# AST1080 register map
File version: 1.0
CPU: CM4 r0p1, little endian, MPU, FPU, 4 interrupt priority bits, 256 interrupts
Registers are 32-bit, read-write, reset 0x0 unless marked. A register's access mark holds for its fields unless they carry their own. Offsets are from the block's base; [hi:lo] are bit positions; {n}, {i} and the like mark numbered series.

## pric_io (part 3 of 3)
Base 0x74100000
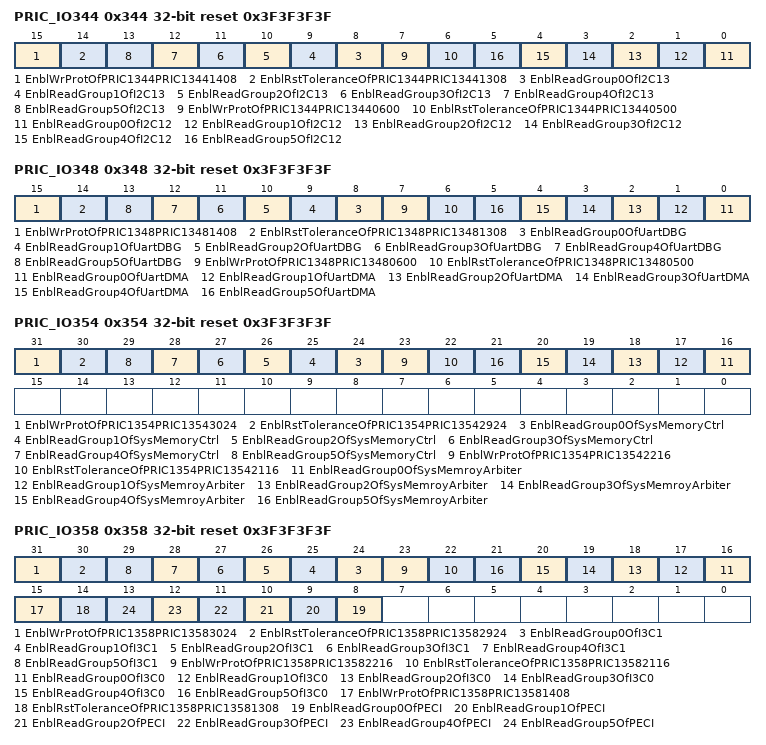
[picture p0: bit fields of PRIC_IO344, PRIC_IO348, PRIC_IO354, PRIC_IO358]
0x344 PRIC_IO344 reset 0x3F3F3F3F — Slave Read Group Setting Register \#17
  [15] EnblWrProtOfPRIC1344PRIC13441408 — Enable Write Protection of PRIC1344PRIC1_344[14:08]
  [14] EnblRstToleranceOfPRIC1344PRIC13441308 — Enable Reset Tolerance of PRIC1344PRIC1_344[13:08]
    0=Reset_By_SRST; 1=Reset_By_SRST_And_PSP_Reset
  [n+8] EnblReadGroup{n}OfI2C13 (n=0..5) — Enable Read Group #{n} of I2C13
  [7] EnblWrProtOfPRIC1344PRIC13440600 — Enable Write Protection of PRIC1344PRIC1_344[06:00]
  [6] EnblRstToleranceOfPRIC1344PRIC13440500 — Enable Reset Tolerance of PRIC1344PRIC1_344[05:00]
    0=Reset_By_SRST; 1=Reset_By_SRST_And_PSP_Reset
  [n] EnblReadGroup{n}OfI2C12 (n=0..5) — Enable Read Group #{n} of I2C12
0x348 PRIC_IO348 reset 0x3F3F3F3F — Slave Read Group Setting Register \#18
  [15] EnblWrProtOfPRIC1348PRIC13481408 — Enable Write Protection of PRIC1348PRIC1_348[14:08]
  [14] EnblRstToleranceOfPRIC1348PRIC13481308 — Enable Reset Tolerance of PRIC1348PRIC1_348[13:08]
    0=Reset_By_SRST; 1=Reset_By_SRST_And_PSP_Reset
  [n+8] EnblReadGroup{n}OfUartDBG (n=0..5) — Enable Read Group #{n} of UartDBG
  [7] EnblWrProtOfPRIC1348PRIC13480600 — Enable Write Protection of PRIC1348PRIC1_348[06:00]
  [6] EnblRstToleranceOfPRIC1348PRIC13480500 — Enable Reset Tolerance of PRIC1348PRIC1_348[05:00]
    0=Reset_By_SRST; 1=Reset_By_SRST_And_PSP_Reset
  [n] EnblReadGroup{n}OfUartDMA (n=0..5) — Enable Read Group #{n} of UartDMA
0x34C PRIC_IO34C reset 0x3F3F3F3F (reset mask 0x0) — Slave Read Group Setting Register \#19
0x350 PRIC_IO350 reset 0x3F3F3F3F (reset mask 0x0) — Slave Read Group Setting Register \#20
0x354 PRIC_IO354 reset 0x3F3F3F3F — Slave Read Group Setting Register \#21
  [31] EnblWrProtOfPRIC1354PRIC13543024 — Enable Write Protection of PRIC1354PRIC1_354[30:24]
  [30] EnblRstToleranceOfPRIC1354PRIC13542924 — Enable Reset Tolerance of PRIC1354PRIC1_354[29:24]
    0=Reset_By_SRST; 1=Reset_By_SRST_And_PSP_Reset
  [n+24] EnblReadGroup{n}OfSysMemoryCtrl (n=0..5) — Enable Read Group #{n} of System Memory Controller
  [23] EnblWrProtOfPRIC1354PRIC13542216 — Enable Write Protection of PRIC1354PRIC1_354[22:16]
  [22] EnblRstToleranceOfPRIC1354PRIC13542116 — Enable Reset Tolerance of PRIC1354PRIC1_354[21:16]
    0=Reset_By_SRST; 1=Reset_By_SRST_And_PSP_Reset
  [n+16] EnblReadGroup{n}OfSysMemroyArbiter (n=0..5) — Enable Read Group #{n} of System Memroy Arbiter
0x358 PRIC_IO358 reset 0x3F3F3F3F — Slave Read Group Setting Register \#22
  [31] EnblWrProtOfPRIC1358PRIC13583024 — Enable Write Protection of PRIC1358PRIC1_358[30:24]
  [30] EnblRstToleranceOfPRIC1358PRIC13582924 — Enable Reset Tolerance of PRIC1358PRIC1_358[29:24]
    0=Reset_By_SRST; 1=Reset_By_SRST_And_PSP_Reset
  [n+24] EnblReadGroup{n}OfI3C1 (n=0..5) — Enable Read Group #{n} of I3C1
  [23] EnblWrProtOfPRIC1358PRIC13582216 — Enable Write Protection of PRIC1358PRIC1_358[22:16]
  [22] EnblRstToleranceOfPRIC1358PRIC13582116 — Enable Reset Tolerance of PRIC1358PRIC1_358[21:16]
    0=Reset_By_SRST; 1=Reset_By_SRST_And_PSP_Reset
  [n+16] EnblReadGroup{n}OfI3C0 (n=0..5) — Enable Read Group #{n} of I3C0
  [15] EnblWrProtOfPRIC1358PRIC13581408 — Enable Write Protection of PRIC1358PRIC1_358[14:08]
  [14] EnblRstToleranceOfPRIC1358PRIC13581308 — Enable Reset Tolerance of PRIC1358PRIC1_358[13:08]
    0=Reset_By_SRST; 1=Reset_By_SRST_And_PSP_Reset
  [n+8] EnblReadGroup{n}OfPECI (n=0..5) — Enable Read Group #{n} of PECI
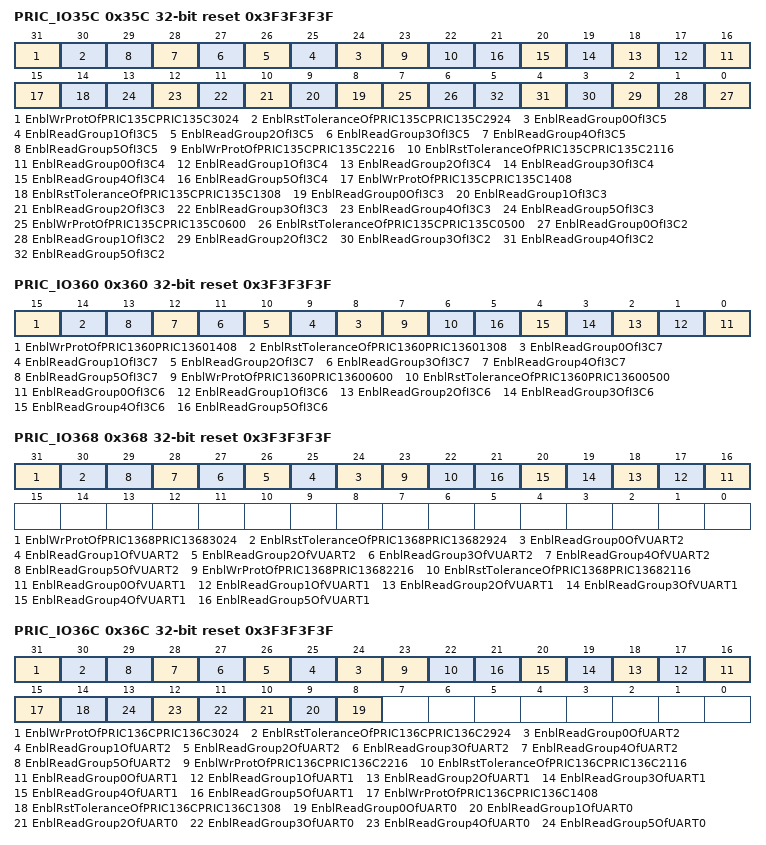
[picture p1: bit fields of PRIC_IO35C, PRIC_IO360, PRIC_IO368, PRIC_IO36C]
0x35C PRIC_IO35C reset 0x3F3F3F3F — Slave Read Group Setting Register \#23
  [31] EnblWrProtOfPRIC135CPRIC135C3024 — Enable Write Protection of PRIC135CPRIC1_35C[30:24]
  [30] EnblRstToleranceOfPRIC135CPRIC135C2924 — Enable Reset Tolerance of PRIC135CPRIC1_35C[29:24]
    0=Reset_By_SRST; 1=Reset_By_SRST_And_PSP_Reset
  [n+24] EnblReadGroup{n}OfI3C5 (n=0..5) — Enable Read Group #{n} of I3C5
  [23] EnblWrProtOfPRIC135CPRIC135C2216 — Enable Write Protection of PRIC135CPRIC1_35C[22:16]
  [22] EnblRstToleranceOfPRIC135CPRIC135C2116 — Enable Reset Tolerance of PRIC135CPRIC1_35C[21:16]
    0=Reset_By_SRST; 1=Reset_By_SRST_And_PSP_Reset
  [n+16] EnblReadGroup{n}OfI3C4 (n=0..5) — Enable Read Group #{n} of I3C4
  [15] EnblWrProtOfPRIC135CPRIC135C1408 — Enable Write Protection of PRIC135CPRIC1_35C[14:08]
  [14] EnblRstToleranceOfPRIC135CPRIC135C1308 — Enable Reset Tolerance of PRIC135CPRIC1_35C[13:08]
    0=Reset_By_SRST; 1=Reset_By_SRST_And_PSP_Reset
  [n+8] EnblReadGroup{n}OfI3C3 (n=0..5) — Enable Read Group #{n} of I3C3
  [7] EnblWrProtOfPRIC135CPRIC135C0600 — Enable Write Protection of PRIC135CPRIC1_35C[06:00]
  [6] EnblRstToleranceOfPRIC135CPRIC135C0500 — Enable Reset Tolerance of PRIC135CPRIC1_35C[05:00]
    0=Reset_By_SRST; 1=Reset_By_SRST_And_PSP_Reset
  [n] EnblReadGroup{n}OfI3C2 (n=0..5) — Enable Read Group #{n} of I3C2
0x360 PRIC_IO360 reset 0x3F3F3F3F — Slave Read Group Setting Register \#24
  [15] EnblWrProtOfPRIC1360PRIC13601408 — Enable Write Protection of PRIC1360PRIC1_360[14:08]
  [14] EnblRstToleranceOfPRIC1360PRIC13601308 — Enable Reset Tolerance of PRIC1360PRIC1_360[13:08]
    0=Reset_By_SRST; 1=Reset_By_SRST_And_PSP_Reset
  [n+8] EnblReadGroup{n}OfI3C7 (n=0..5) — Enable Read Group #{n} of I3C7
  [7] EnblWrProtOfPRIC1360PRIC13600600 — Enable Write Protection of PRIC1360PRIC1_360[06:00]
  [6] EnblRstToleranceOfPRIC1360PRIC13600500 — Enable Reset Tolerance of PRIC1360PRIC1_360[05:00]
    0=Reset_By_SRST; 1=Reset_By_SRST_And_PSP_Reset
  [n] EnblReadGroup{n}OfI3C6 (n=0..5) — Enable Read Group #{n} of I3C6
0x364 PRIC_IO364 reset 0x3F3F3F3F (reset mask 0x0) — Slave Read Group Setting Register \#25
0x368 PRIC_IO368 reset 0x3F3F3F3F — Slave Read Group Setting Register \#26
  [31] EnblWrProtOfPRIC1368PRIC13683024 — Enable Write Protection of PRIC1368PRIC1_368[30:24]
  [30] EnblRstToleranceOfPRIC1368PRIC13682924 — Enable Reset Tolerance of PRIC1368PRIC1_368[29:24]
    0=Reset_By_SRST; 1=Reset_By_SRST_And_PSP_Reset
  [n+24] EnblReadGroup{n}OfVUART2 (n=0..5) — Enable Read Group #{n} of VUART2
  [23] EnblWrProtOfPRIC1368PRIC13682216 — Enable Write Protection of PRIC1368PRIC1_368[22:16]
  [22] EnblRstToleranceOfPRIC1368PRIC13682116 — Enable Reset Tolerance of PRIC1368PRIC1_368[21:16]
    0=Reset_By_SRST; 1=Reset_By_SRST_And_PSP_Reset
  [n+16] EnblReadGroup{n}OfVUART1 (n=0..5) — Enable Read Group #{n} of VUART1
0x36C PRIC_IO36C reset 0x3F3F3F3F — Slave Read Group Setting Register \#27
  [31] EnblWrProtOfPRIC136CPRIC136C3024 — Enable Write Protection of PRIC136CPRIC1_36C[30:24]
  [30] EnblRstToleranceOfPRIC136CPRIC136C2924 — Enable Reset Tolerance of PRIC136CPRIC1_36C[29:24]
    0=Reset_By_SRST; 1=Reset_By_SRST_And_PSP_Reset
  [n+24] EnblReadGroup{n}OfUART2 (n=0..5) — Enable Read Group #{n} of UART2
  [23] EnblWrProtOfPRIC136CPRIC136C2216 — Enable Write Protection of PRIC136CPRIC1_36C[22:16]
  [22] EnblRstToleranceOfPRIC136CPRIC136C2116 — Enable Reset Tolerance of PRIC136CPRIC1_36C[21:16]
    0=Reset_By_SRST; 1=Reset_By_SRST_And_PSP_Reset
  [n+16] EnblReadGroup{n}OfUART1 (n=0..5) — Enable Read Group #{n} of UART1
  [15] EnblWrProtOfPRIC136CPRIC136C1408 — Enable Write Protection of PRIC136CPRIC1_36C[14:08]
  [14] EnblRstToleranceOfPRIC136CPRIC136C1308 — Enable Reset Tolerance of PRIC136CPRIC1_36C[13:08]
    0=Reset_By_SRST; 1=Reset_By_SRST_And_PSP_Reset
  [n+8] EnblReadGroup{n}OfUART0 (n=0..5) — Enable Read Group #{n} of UART0
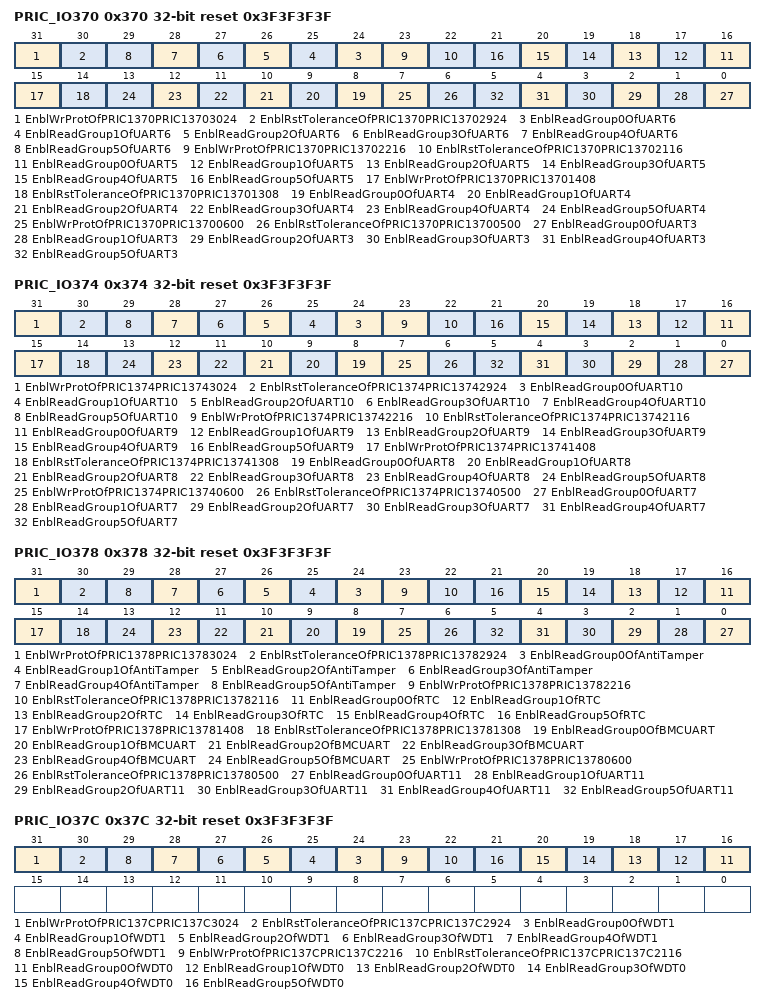
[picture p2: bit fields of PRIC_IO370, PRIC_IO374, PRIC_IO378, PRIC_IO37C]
0x370 PRIC_IO370 reset 0x3F3F3F3F — Slave Read Group Setting Register \#28
  [31] EnblWrProtOfPRIC1370PRIC13703024 — Enable Write Protection of PRIC1370PRIC1_370[30:24]
  [30] EnblRstToleranceOfPRIC1370PRIC13702924 — Enable Reset Tolerance of PRIC1370PRIC1_370[29:24]
    0=Reset_By_SRST; 1=Reset_By_SRST_And_PSP_Reset
  [n+24] EnblReadGroup{n}OfUART6 (n=0..5) — Enable Read Group #{n} of UART6
  [23] EnblWrProtOfPRIC1370PRIC13702216 — Enable Write Protection of PRIC1370PRIC1_370[22:16]
  [22] EnblRstToleranceOfPRIC1370PRIC13702116 — Enable Reset Tolerance of PRIC1370PRIC1_370[21:16]
    0=Reset_By_SRST; 1=Reset_By_SRST_And_PSP_Reset
  [n+16] EnblReadGroup{n}OfUART5 (n=0..5) — Enable Read Group #{n} of UART5
  [15] EnblWrProtOfPRIC1370PRIC13701408 — Enable Write Protection of PRIC1370PRIC1_370[14:08]
  [14] EnblRstToleranceOfPRIC1370PRIC13701308 — Enable Reset Tolerance of PRIC1370PRIC1_370[13:08]
    0=Reset_By_SRST; 1=Reset_By_SRST_And_PSP_Reset
  [n+8] EnblReadGroup{n}OfUART4 (n=0..5) — Enable Read Group #{n} of UART4
  [7] EnblWrProtOfPRIC1370PRIC13700600 — Enable Write Protection of PRIC1370PRIC1_370[06:00]
  [6] EnblRstToleranceOfPRIC1370PRIC13700500 — Enable Reset Tolerance of PRIC1370PRIC1_370[05:00]
    0=Reset_By_SRST; 1=Reset_By_SRST_And_PSP_Reset
  [n] EnblReadGroup{n}OfUART3 (n=0..5) — Enable Read Group #{n} of UART3
0x374 PRIC_IO374 reset 0x3F3F3F3F — Slave Read Group Setting Register \#29
  [31] EnblWrProtOfPRIC1374PRIC13743024 — Enable Write Protection of PRIC1374PRIC1_374[30:24]
  [30] EnblRstToleranceOfPRIC1374PRIC13742924 — Enable Reset Tolerance of PRIC1374PRIC1_374[29:24]
    0=Reset_By_SRST; 1=Reset_By_SRST_And_PSP_Reset
  [n+24] EnblReadGroup{n}OfUART10 (n=0..5) — Enable Read Group #{n} of UART10
  [23] EnblWrProtOfPRIC1374PRIC13742216 — Enable Write Protection of PRIC1374PRIC1_374[22:16]
  [22] EnblRstToleranceOfPRIC1374PRIC13742116 — Enable Reset Tolerance of PRIC1374PRIC1_374[21:16]
    0=Reset_By_SRST; 1=Reset_By_SRST_And_PSP_Reset
  [n+16] EnblReadGroup{n}OfUART9 (n=0..5) — Enable Read Group #{n} of UART9
  [15] EnblWrProtOfPRIC1374PRIC13741408 — Enable Write Protection of PRIC1374PRIC1_374[14:08]
  [14] EnblRstToleranceOfPRIC1374PRIC13741308 — Enable Reset Tolerance of PRIC1374PRIC1_374[13:08]
    0=Reset_By_SRST; 1=Reset_By_SRST_And_PSP_Reset
  [n+8] EnblReadGroup{n}OfUART8 (n=0..5) — Enable Read Group #{n} of UART8
  [7] EnblWrProtOfPRIC1374PRIC13740600 — Enable Write Protection of PRIC1374PRIC1_374[06:00]
  [6] EnblRstToleranceOfPRIC1374PRIC13740500 — Enable Reset Tolerance of PRIC1374PRIC1_374[05:00]
    0=Reset_By_SRST; 1=Reset_By_SRST_And_PSP_Reset
  [n] EnblReadGroup{n}OfUART7 (n=0..5) — Enable Read Group #{n} of UART7
0x378 PRIC_IO378 reset 0x3F3F3F3F — Slave Read Group Setting Register \#30
  [31] EnblWrProtOfPRIC1378PRIC13783024 — Enable Write Protection of PRIC1378PRIC1_378[30:24]
  [30] EnblRstToleranceOfPRIC1378PRIC13782924 — Enable Reset Tolerance of PRIC1378PRIC1_378[29:24]
    0=Reset_By_SRST; 1=Reset_By_SRST_And_PSP_Reset
  [n+24] EnblReadGroup{n}OfAntiTamper (n=0..5) — Enable Read Group #{n} of Anti Tamper
  [23] EnblWrProtOfPRIC1378PRIC13782216 — Enable Write Protection of PRIC1378PRIC1_378[22:16]
  [22] EnblRstToleranceOfPRIC1378PRIC13782116 — Enable Reset Tolerance of PRIC1378PRIC1_378[21:16]
    0=Reset_By_SRST; 1=Reset_By_SRST_And_PSP_Reset
  [n+16] EnblReadGroup{n}OfRTC (n=0..5) — Enable Read Group #{n} of RTC
  [15] EnblWrProtOfPRIC1378PRIC13781408 — Enable Write Protection of PRIC1378PRIC1_378[14:08]
  [14] EnblRstToleranceOfPRIC1378PRIC13781308 — Enable Reset Tolerance of PRIC1378PRIC1_378[13:08]
    0=Reset_By_SRST; 1=Reset_By_SRST_And_PSP_Reset
  [n+8] EnblReadGroup{n}OfBMCUART (n=0..5) — Enable Read Group #{n} of BMC UART
  [7] EnblWrProtOfPRIC1378PRIC13780600 — Enable Write Protection of PRIC1378PRIC1_378[06:00]
  [6] EnblRstToleranceOfPRIC1378PRIC13780500 — Enable Reset Tolerance of PRIC1378PRIC1_378[05:00]
    0=Reset_By_SRST; 1=Reset_By_SRST_And_PSP_Reset
  [n] EnblReadGroup{n}OfUART11 (n=0..5) — Enable Read Group #{n} of UART11
0x37C PRIC_IO37C reset 0x3F3F3F3F — Slave Read Group Setting Register \#31
  [31] EnblWrProtOfPRIC137CPRIC137C3024 — Enable Write Protection of PRIC137CPRIC1_37C[30:24]
  [30] EnblRstToleranceOfPRIC137CPRIC137C2924 — Enable Reset Tolerance of PRIC137CPRIC1_37C[29:24]
    0=Reset_By_SRST; 1=Reset_By_SRST_And_PSP_Reset
  [n+24] EnblReadGroup{n}OfWDT1 (n=0..5) — Enable Read Group #{n} of WDT 1
  [23] EnblWrProtOfPRIC137CPRIC137C2216 — Enable Write Protection of PRIC137CPRIC1_37C[22:16]
  [22] EnblRstToleranceOfPRIC137CPRIC137C2116 — Enable Reset Tolerance of PRIC137CPRIC1_37C[21:16]
    0=Reset_By_SRST; 1=Reset_By_SRST_And_PSP_Reset
  [n+16] EnblReadGroup{n}OfWDT0 (n=0..5) — Enable Read Group #{n} of WDT 0
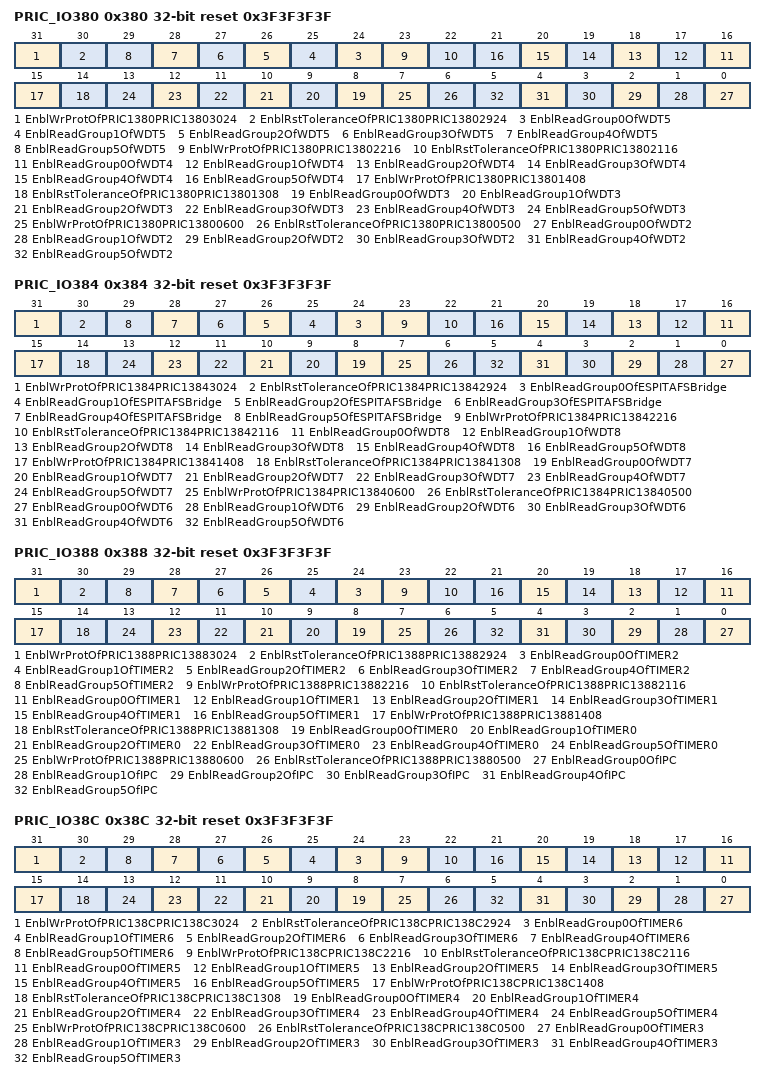
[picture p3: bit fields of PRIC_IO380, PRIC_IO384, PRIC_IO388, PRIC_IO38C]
0x380 PRIC_IO380 reset 0x3F3F3F3F — Slave Read Group Setting Register \#32
  [31] EnblWrProtOfPRIC1380PRIC13803024 — Enable Write Protection of PRIC1380PRIC1_380[30:24]
  [30] EnblRstToleranceOfPRIC1380PRIC13802924 — Enable Reset Tolerance of PRIC1380PRIC1_380[29:24]
    0=Reset_By_SRST; 1=Reset_By_SRST_And_PSP_Reset
  [n+24] EnblReadGroup{n}OfWDT5 (n=0..5) — Enable Read Group #{n} of WDT 5
  [23] EnblWrProtOfPRIC1380PRIC13802216 — Enable Write Protection of PRIC1380PRIC1_380[22:16]
  [22] EnblRstToleranceOfPRIC1380PRIC13802116 — Enable Reset Tolerance of PRIC1380PRIC1_380[21:16]
    0=Reset_By_SRST; 1=Reset_By_SRST_And_PSP_Reset
  [n+16] EnblReadGroup{n}OfWDT4 (n=0..5) — Enable Read Group #{n} of WDT 4
  [15] EnblWrProtOfPRIC1380PRIC13801408 — Enable Write Protection of PRIC1380PRIC1_380[14:08]
  [14] EnblRstToleranceOfPRIC1380PRIC13801308 — Enable Reset Tolerance of PRIC1380PRIC1_380[13:08]
    0=Reset_By_SRST; 1=Reset_By_SRST_And_PSP_Reset
  [n+8] EnblReadGroup{n}OfWDT3 (n=0..5) — Enable Read Group #{n} of WDT 3
  [7] EnblWrProtOfPRIC1380PRIC13800600 — Enable Write Protection of PRIC1380PRIC1_380[06:00]
  [6] EnblRstToleranceOfPRIC1380PRIC13800500 — Enable Reset Tolerance of PRIC1380PRIC1_380[05:00]
    0=Reset_By_SRST; 1=Reset_By_SRST_And_PSP_Reset
  [n] EnblReadGroup{n}OfWDT2 (n=0..5) — Enable Read Group #{n} of WDT 2
0x384 PRIC_IO384 reset 0x3F3F3F3F — Slave Read Group Setting Register \#33
  [31] EnblWrProtOfPRIC1384PRIC13843024 — Enable Write Protection of PRIC1384PRIC1_384[30:24]
  [30] EnblRstToleranceOfPRIC1384PRIC13842924 — Enable Reset Tolerance of PRIC1384PRIC1_384[29:24]
    0=Reset_By_SRST; 1=Reset_By_SRST_And_PSP_Reset
  [n+24] EnblReadGroup{n}OfESPITAFSBridge (n=0..5) — Enable Read Group #{n} of eSPI TAFS Bridge
  [23] EnblWrProtOfPRIC1384PRIC13842216 — Enable Write Protection of PRIC1384PRIC1_384[22:16]
  [22] EnblRstToleranceOfPRIC1384PRIC13842116 — Enable Reset Tolerance of PRIC1384PRIC1_384[21:16]
    0=Reset_By_SRST; 1=Reset_By_SRST_And_PSP_Reset
  [n+16] EnblReadGroup{n}OfWDT8 (n=0..5) — Enable Read Group #{n} of WDT 8
  [15] EnblWrProtOfPRIC1384PRIC13841408 — Enable Write Protection of PRIC1384PRIC1_384[14:08]
  [14] EnblRstToleranceOfPRIC1384PRIC13841308 — Enable Reset Tolerance of PRIC1384PRIC1_384[13:08]
    0=Reset_By_SRST; 1=Reset_By_SRST_And_PSP_Reset
  [n+8] EnblReadGroup{n}OfWDT7 (n=0..5) — Enable Read Group #{n} of WDT 7
  [7] EnblWrProtOfPRIC1384PRIC13840600 — Enable Write Protection of PRIC1384PRIC1_384[06:00]
  [6] EnblRstToleranceOfPRIC1384PRIC13840500 — Enable Reset Tolerance of PRIC1384PRIC1_384[05:00]
    0=Reset_By_SRST; 1=Reset_By_SRST_And_PSP_Reset
  [n] EnblReadGroup{n}OfWDT6 (n=0..5) — Enable Read Group #{n} of WDT 6
0x388 PRIC_IO388 reset 0x3F3F3F3F — Slave Read Group Setting Register \#34
  [31] EnblWrProtOfPRIC1388PRIC13883024 — Enable Write Protection of PRIC1388PRIC1_388[30:24]
  [30] EnblRstToleranceOfPRIC1388PRIC13882924 — Enable Reset Tolerance of PRIC1388PRIC1_388[29:24]
    0=Reset_By_SRST; 1=Reset_By_SRST_And_PSP_Reset
  [n+24] EnblReadGroup{n}OfTIMER2 (n=0..5) — Enable Read Group #{n} of TIMER2
  [23] EnblWrProtOfPRIC1388PRIC13882216 — Enable Write Protection of PRIC1388PRIC1_388[22:16]
  [22] EnblRstToleranceOfPRIC1388PRIC13882116 — Enable Reset Tolerance of PRIC1388PRIC1_388[21:16]
    0=Reset_By_SRST; 1=Reset_By_SRST_And_PSP_Reset
  [n+16] EnblReadGroup{n}OfTIMER1 (n=0..5) — Enable Read Group #{n} of TIMER1
  [15] EnblWrProtOfPRIC1388PRIC13881408 — Enable Write Protection of PRIC1388PRIC1_388[14:08]
  [14] EnblRstToleranceOfPRIC1388PRIC13881308 — Enable Reset Tolerance of PRIC1388PRIC1_388[13:08]
    0=Reset_By_SRST; 1=Reset_By_SRST_And_PSP_Reset
  [n+8] EnblReadGroup{n}OfTIMER0 (n=0..5) — Enable Read Group #{n} of TIMER0
  [7] EnblWrProtOfPRIC1388PRIC13880600 — Enable Write Protection of PRIC1388PRIC1_388[06:00]
  [6] EnblRstToleranceOfPRIC1388PRIC13880500 — Enable Reset Tolerance of PRIC1388PRIC1_388[05:00]
    0=Reset_By_SRST; 1=Reset_By_SRST_And_PSP_Reset
  [n] EnblReadGroup{n}OfIPC (n=0..5) — Enable Read Group #{n} of IPC
0x38C PRIC_IO38C reset 0x3F3F3F3F — Slave Read Group Setting Register \#35
  [31] EnblWrProtOfPRIC138CPRIC138C3024 — Enable Write Protection of PRIC138CPRIC1_38C[30:24]
  [30] EnblRstToleranceOfPRIC138CPRIC138C2924 — Enable Reset Tolerance of PRIC138CPRIC1_38C[29:24]
    0=Reset_By_SRST; 1=Reset_By_SRST_And_PSP_Reset
  [n+24] EnblReadGroup{n}OfTIMER6 (n=0..5) — Enable Read Group #{n} of TIMER6
  [23] EnblWrProtOfPRIC138CPRIC138C2216 — Enable Write Protection of PRIC138CPRIC1_38C[22:16]
  [22] EnblRstToleranceOfPRIC138CPRIC138C2116 — Enable Reset Tolerance of PRIC138CPRIC1_38C[21:16]
    0=Reset_By_SRST; 1=Reset_By_SRST_And_PSP_Reset
  [n+16] EnblReadGroup{n}OfTIMER5 (n=0..5) — Enable Read Group #{n} of TIMER5
  [15] EnblWrProtOfPRIC138CPRIC138C1408 — Enable Write Protection of PRIC138CPRIC1_38C[14:08]
  [14] EnblRstToleranceOfPRIC138CPRIC138C1308 — Enable Reset Tolerance of PRIC138CPRIC1_38C[13:08]
    0=Reset_By_SRST; 1=Reset_By_SRST_And_PSP_Reset
  [n+8] EnblReadGroup{n}OfTIMER4 (n=0..5) — Enable Read Group #{n} of TIMER4
  [7] EnblWrProtOfPRIC138CPRIC138C0600 — Enable Write Protection of PRIC138CPRIC1_38C[06:00]
  [6] EnblRstToleranceOfPRIC138CPRIC138C0500 — Enable Reset Tolerance of PRIC138CPRIC1_38C[05:00]
    0=Reset_By_SRST; 1=Reset_By_SRST_And_PSP_Reset
  [n] EnblReadGroup{n}OfTIMER3 (n=0..5) — Enable Read Group #{n} of TIMER3
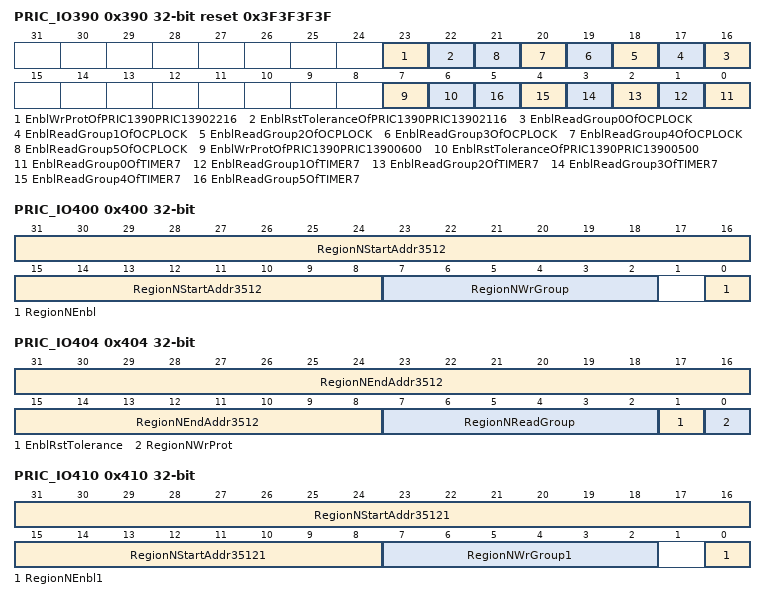
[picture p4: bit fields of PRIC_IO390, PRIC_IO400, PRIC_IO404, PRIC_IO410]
0x390 PRIC_IO390 reset 0x3F3F3F3F — Slave Read Group Setting Register \#36
  [23] EnblWrProtOfPRIC1390PRIC13902216 — Enable Write Protection of PRIC1390PRIC1_390[22:16]
  [22] EnblRstToleranceOfPRIC1390PRIC13902116 — Enable Reset Tolerance of PRIC1390PRIC1_390[21:16]
    0=Reset_By_SRST; 1=Reset_By_SRST_And_PSP_Reset
  [n+16] EnblReadGroup{n}OfOCPLOCK (n=0..5) — Enable Read Group #{n} of OCP_LOCK
  [7] EnblWrProtOfPRIC1390PRIC13900600 — Enable Write Protection of PRIC1390PRIC1_390[06:00]
  [6] EnblRstToleranceOfPRIC1390PRIC13900500 — Enable Reset Tolerance of PRIC1390PRIC1_390[05:00]
    0=Reset_By_SRST; 1=Reset_By_SRST_And_PSP_Reset
  [n] EnblReadGroup{n}OfTIMER7 (n=0..5) — Enable Read Group #{n} of TIMER7
0x394 PRIC_IO394 reset 0x3F3F3F3F (reset mask 0x0) — Slave Read Group Setting Register \#37
0x398 PRIC_IO398 reset 0x3F3F3F3F (reset mask 0x0) — Slave Read Group Setting Register \#38
0x39C PRIC_IO39C reset 0x3F3F3F3F (reset mask 0x0) — Slave Read Group Setting Register \#39
0x3A0 PRIC_IO3A0 reset 0x3F3F3F3F (reset mask 0x0) — Slave Read Group Setting Register \#40
0x3A4 PRIC_IO3A4 reset 0x3F3F3F3F (reset mask 0x0) — Slave Read Group Setting Register \#41
0x3A8 PRIC_IO3A8 reset 0x3F3F3F3F (reset mask 0x0) — Slave Read Group Setting Register \#42
0x3AC PRIC_IO3AC reset 0x3F3F3F3F (reset mask 0x0) — Slave Read Group Setting Register \#43
0x3B0 PRIC_IO3B0 reset 0x3F3F3F3F (reset mask 0x0) — Slave Read Group Setting Register \#44
0x3B4 PRIC_IO3B4 reset 0x3F3F3F3F (reset mask 0x0) — Slave Read Group Setting Register \#45
0x3B8 PRIC_IO3B8 reset 0x3F3F3F3F (reset mask 0x0) — Slave Read Group Setting Register \#46
0x3BC PRIC_IO3BC reset 0x3F3F3F3F (reset mask 0x0) — Slave Read Group Setting Register \#47
0x3C0 PRIC_IO3C0 reset 0x3F3F3F3F (reset mask 0x0) — Slave Read Group Setting Register \#48
0x3C4 PRIC_IO3C4 reset 0x3F3F3F3F (reset mask 0x0) — Slave Read Group Setting Register \#49
0x3C8 PRIC_IO3C8 reset 0x3F3F3F3F (reset mask 0x0) — Slave Read Group Setting Register \#50
0x3CC PRIC_IO3CC reset 0x3F3F3F3F (reset mask 0x0) — Slave Read Group Setting Register \#51
0x3D0 PRIC_IO3D0 reset 0x3F3F3F3F (reset mask 0x0) — Slave Read Group Setting Register \#52
0x3D4 PRIC_IO3D4 reset 0x3F3F3F3F (reset mask 0x0) — Slave Read Group Setting Register \#53
0x3D8 PRIC_IO3D8 reset 0x3F3F3F3F (reset mask 0x0) — Slave Read Group Setting Register \#54
0x3DC PRIC_IO3DC reset 0x3F3F3F3F (reset mask 0x0) — Slave Read Group Setting Register \#55
0x3E0 PRIC_IO3E0 reset 0x3F3F3F3F (reset mask 0x0) — Slave Read Group Setting Register \#56
0x3E4 PRIC_IO3E4 reset 0x3F3F3F3F (reset mask 0x0) — Slave Read Group Setting Register \#57
0x3E8 PRIC_IO3E8 reset 0x3F3F3F3F (reset mask 0x0) — Slave Read Group Setting Register \#58
0x3EC PRIC_IO3EC reset 0x3F3F3F3F (reset mask 0x0) — Slave Read Group Setting Register \#59
0x3F0 PRIC_IO3F0 reset 0x3F3F3F3F (reset mask 0x0) — Slave Read Group Setting Register \#60
0x3F4 PRIC_IO3F4 reset 0x3F3F3F3F (reset mask 0x0) — Slave Read Group Setting Register \#61
0x3F8 PRIC_IO3F8 reset 0x3F3F3F3F (reset mask 0x0) — Slave Read Group Setting Register \#62
0x3FC PRIC_IO3FC reset 0x3F3F3F3F (reset mask 0x0) — Slave Read Group Setting Register \#63
0x400 PRIC_IO400 — Memory Region Proection for AHB Masters Register \#0
  [31:8] RegionNStartAddr3512 — Region #N Start Address[35:12]
  [7:2] RegionNWrGroup — Region #N Write Group
  [0] RegionNEnbl — Region #N Enable
0x404 PRIC_IO404 — Memory Region Proection for AHB Masters Register \#1
  [31:8] RegionNEndAddr3512 — Region #N End Address[35:12]
  [7:2] RegionNReadGroup
  [1] EnblRstTolerance — Enable Reset Tolerance
    0=Reset_By_SRST; 1=Reset_By_SRST_And_PSP_Reset
  [0] RegionNWrProt — Region #N Write Protection
0x408 PRIC_IO408 — Memory Region Proection for AHB Masters Register \#2
  [31:0] RegionNWrMasters — Region #N Write Masters
0x40C PRIC_IO40C — Memory Region Proection for AHB Masters Register \#3
  [31:0] RegionNReadMasters
0x410 PRIC_IO410 — Memory Region Proection for AHB Masters Register \#4
  [31:8] RegionNStartAddr35121 — Region #N Start Address[35:12]
  [7:2] RegionNWrGroup1 — Region #N Write Group
  [0] RegionNEnbl1 — Region #N Enable
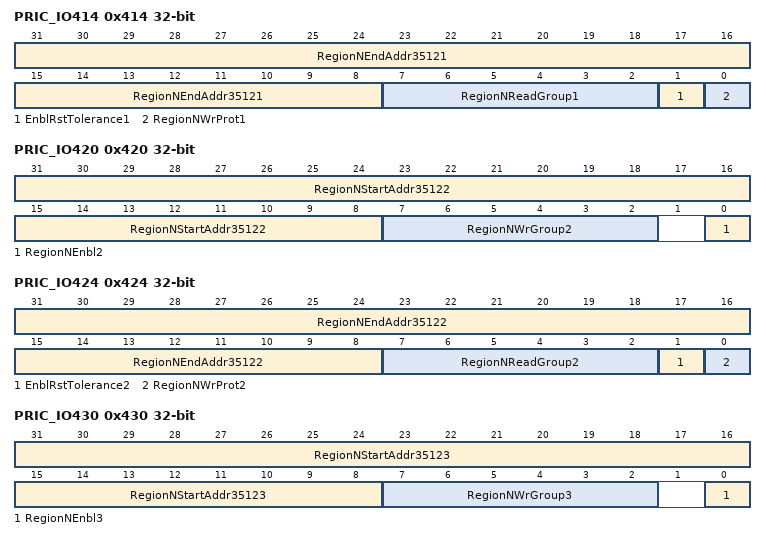
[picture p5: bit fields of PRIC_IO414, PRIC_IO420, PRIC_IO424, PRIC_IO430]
0x414 PRIC_IO414 — Memory Region Proection for AHB Masters Register \#5
  [31:8] RegionNEndAddr35121 — Region #N End Address[35:12]
  [7:2] RegionNReadGroup1 — Region #N Read Group
  [1] EnblRstTolerance1 — Enable Reset Tolerance
    0=Reset_By_SRST; 1=Reset_By_SRST_And_PSP_Reset
  [0] RegionNWrProt1 — Region #N Write Protection
0x418 PRIC_IO418 — Memory Region Proection for AHB Masters Register \#6
  [31:0] RegionNWrMasters1 — Region #N Write Masters
{0x18C+0x10*i} PRIC_IO{i}C (i=41..46) — Memory Region Proection for AHB Masters Register \#{4i-157}
  [31:0] RegionNReadMasters{i-40} — Region #N Read Masters
0x420 PRIC_IO420 — Memory Region Proection for AHB Masters Register \#8
  [31:8] RegionNStartAddr35122 — Region #N Start Address[35:12]
  [7:2] RegionNWrGroup2 — Region #N Write Group
  [0] RegionNEnbl2 — Region #N Enable
0x424 PRIC_IO424 — Memory Region Proection for AHB Masters Register \#9
  [31:8] RegionNEndAddr35122 — Region #N End Address[35:12]
  [7:2] RegionNReadGroup2 — Region #N Read Group
  [1] EnblRstTolerance2 — Enable Reset Tolerance
    0=Reset_By_SRST; 1=Reset_By_SRST_And_PSP_Reset
  [0] RegionNWrProt2 — Region #N Write Protection
0x428 PRIC_IO428 — Memory Region Proection for AHB Masters Register \#10
  [31:0] RegionNWrMasters2 — Region #N Write Masters
0x430 PRIC_IO430 — Memory Region Proection for AHB Masters Register \#12
  [31:8] RegionNStartAddr35123 — Region #N Start Address[35:12]
  [7:2] RegionNWrGroup3 — Region #N Write Group
  [0] RegionNEnbl3 — Region #N Enable
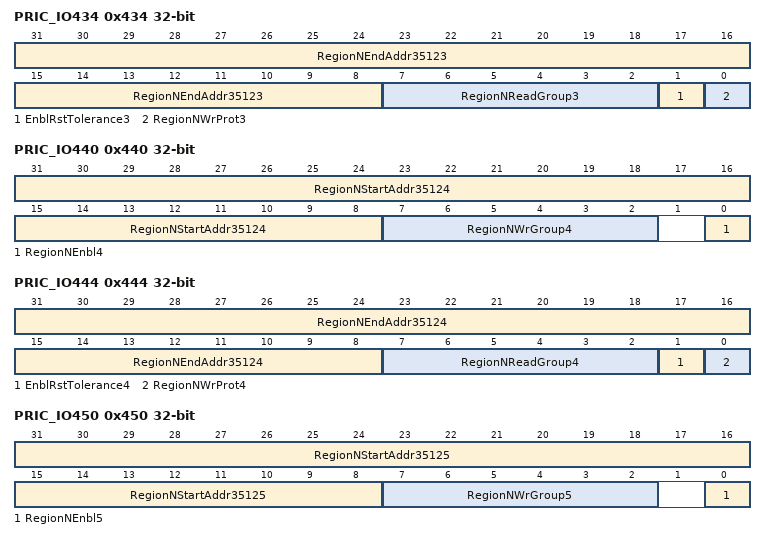
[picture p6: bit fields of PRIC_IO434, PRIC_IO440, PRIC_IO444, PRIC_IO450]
0x434 PRIC_IO434 — Memory Region Proection for AHB Masters Register \#13
  [31:8] RegionNEndAddr35123 — Region #N End Address[35:12]
  [7:2] RegionNReadGroup3 — Region #N Read Group
  [1] EnblRstTolerance3 — Enable Reset Tolerance
    0=Reset_By_SRST; 1=Reset_By_SRST_And_PSP_Reset
  [0] RegionNWrProt3 — Region #N Write Protection
0x438 PRIC_IO438 — Memory Region Proection for AHB Masters Register \#14
  [31:0] RegionNWrMasters3 — Region #N Write Masters
0x440 PRIC_IO440 — Memory Region Proection for AHB Masters Register \#16
  [31:8] RegionNStartAddr35124 — Region #N Start Address[35:12]
  [7:2] RegionNWrGroup4 — Region #N Write Group
  [0] RegionNEnbl4 — Region #N Enable
0x444 PRIC_IO444 — Memory Region Proection for AHB Masters Register \#17
  [31:8] RegionNEndAddr35124 — Region #N End Address[35:12]
  [7:2] RegionNReadGroup4 — Region #N Read Group
  [1] EnblRstTolerance4 — Enable Reset Tolerance
    0=Reset_By_SRST; 1=Reset_By_SRST_And_PSP_Reset
  [0] RegionNWrProt4 — Region #N Write Protection
0x448 PRIC_IO448 — Memory Region Proection for AHB Masters Register \#18
  [31:0] RegionNWrMasters4 — Region #N Write Masters
0x450 PRIC_IO450 — Memory Region Proection for AHB Masters Register \#20
  [31:8] RegionNStartAddr35125 — Region #N Start Address[35:12]
  [7:2] RegionNWrGroup5 — Region #N Write Group
  [0] RegionNEnbl5 — Region #N Enable
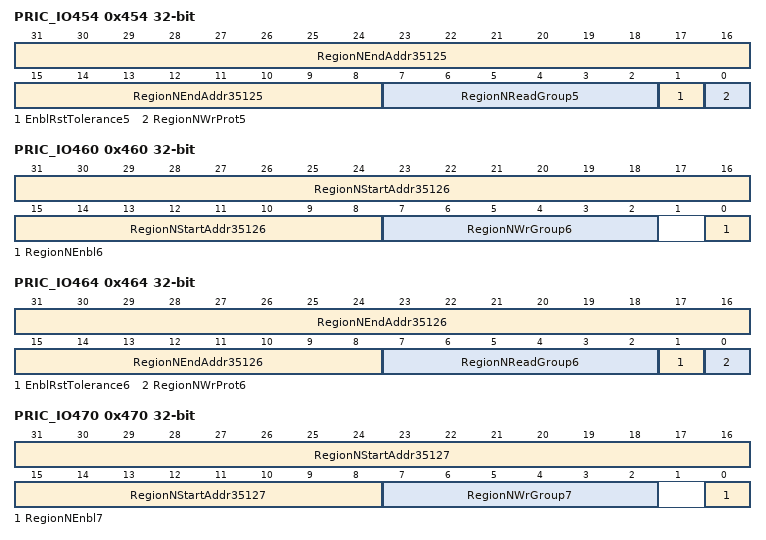
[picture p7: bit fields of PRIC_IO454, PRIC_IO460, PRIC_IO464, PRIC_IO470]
0x454 PRIC_IO454 — Memory Region Proection for AHB Masters Register \#21
  [31:8] RegionNEndAddr35125 — Region #N End Address[35:12]
  [7:2] RegionNReadGroup5 — Region #N Read Group
  [1] EnblRstTolerance5 — Enable Reset Tolerance
    0=Reset_By_SRST; 1=Reset_By_SRST_And_PSP_Reset
  [0] RegionNWrProt5 — Region #N Write Protection
0x458 PRIC_IO458 — Memory Region Proection for AHB Masters Register \#22
  [31:0] RegionNWrMasters5 — Region #N Write Masters
0x460 PRIC_IO460 — Memory Region Proection for AHB Masters Register \#24
  [31:8] RegionNStartAddr35126 — Region #N Start Address[35:12]
  [7:2] RegionNWrGroup6 — Region #N Write Group
  [0] RegionNEnbl6 — Region #N Enable
0x464 PRIC_IO464 — Memory Region Proection for AHB Masters Register \#25
  [31:8] RegionNEndAddr35126 — Region #N End Address[35:12]
  [7:2] RegionNReadGroup6 — Region #N Read Group
  [1] EnblRstTolerance6 — Enable Reset Tolerance
    0=Reset_By_SRST; 1=Reset_By_SRST_And_PSP_Reset
  [0] RegionNWrProt6 — Region #N Write Protection
0x468 PRIC_IO468 — Memory Region Proection for AHB Masters Register \#26
  [31:0] RegionNWrMasters6 — Region #N Write Masters
0x470 PRIC_IO470 — Memory Region Proection for AHB Masters Register \#28
  [31:8] RegionNStartAddr35127 — Region #N Start Address[35:12]
  [7:2] RegionNWrGroup7 — Region #N Write Group
  [0] RegionNEnbl7 — Region #N Enable
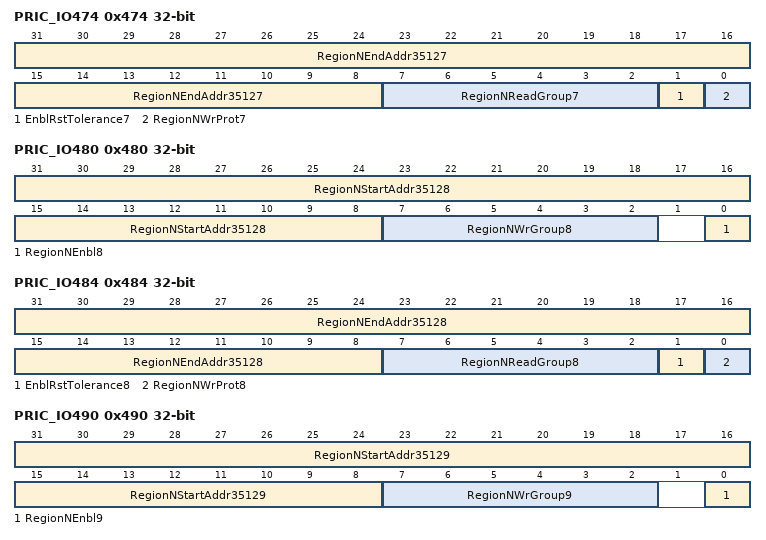
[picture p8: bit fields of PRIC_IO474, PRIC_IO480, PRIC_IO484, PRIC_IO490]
0x474 PRIC_IO474 — Memory Region Proection for AHB Masters Register \#29
  [31:8] RegionNEndAddr35127 — Region #N End Address[35:12]
  [7:2] RegionNReadGroup7 — Region #N Read Group
  [1] EnblRstTolerance7 — Enable Reset Tolerance
    0=Reset_By_SRST; 1=Reset_By_SRST_And_PSP_Reset
  [0] RegionNWrProt7 — Region #N Write Protection
0x478 PRIC_IO478 — Memory Region Proection for AHB Masters Register \#20
  [31:0] RegionNWrMasters7 — Region #N Write Masters
0x47C PRIC_IO47C — Memory Region Proection for AHB Masters Register \#21
  [31:0] RegionNReadMasters7 — Region #N Read Masters
0x480 PRIC_IO480 — Memory Region Proection for AHB Masters Register \#32
  [31:8] RegionNStartAddr35128 — Region #N Start Address[35:12]
  [7:2] RegionNWrGroup8 — Region #N Write Group
  [0] RegionNEnbl8 — Region #N Enable
0x484 PRIC_IO484 — Memory Region Proection for AHB Masters Register \#33
  [31:8] RegionNEndAddr35128 — Region #N End Address[35:12]
  [7:2] RegionNReadGroup8 — Region #N Read Group
  [1] EnblRstTolerance8 — Enable Reset Tolerance
    0=Reset_By_SRST; 1=Reset_By_SRST_And_PSP_Reset
  [0] RegionNWrProt8 — Region #N Write Protection
0x488 PRIC_IO488 — Memory Region Proection for AHB Masters Register \#34
  [31:0] RegionNWrMasters8 — Region #N Write Masters
0x48C PRIC_IO48C — Memory Region Proection for AHB Masters Register \#35
  [31:0] RegionNReadMasters8 — Region #N Read Masters
0x490 PRIC_IO490 — Memory Region Proection for AHB Masters Register \#36
  [31:8] RegionNStartAddr35129 — Region #N Start Address[35:12]
  [7:2] RegionNWrGroup9 — Region #N Write Group
  [0] RegionNEnbl9 — Region #N Enable
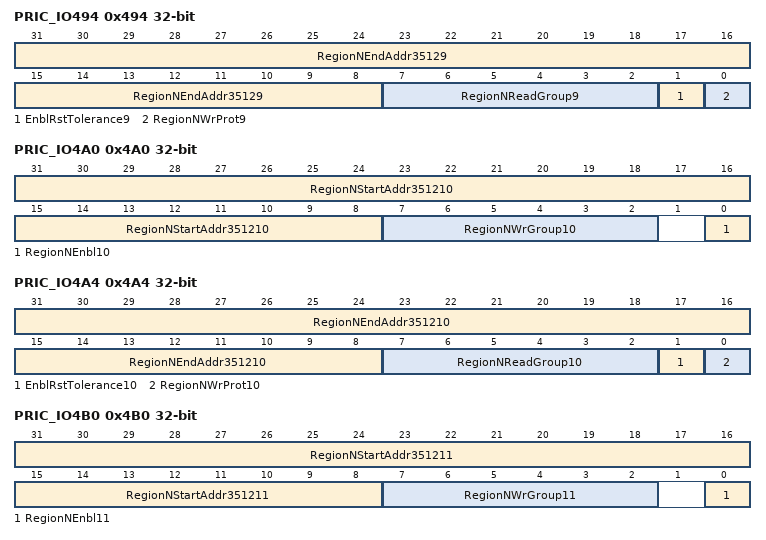
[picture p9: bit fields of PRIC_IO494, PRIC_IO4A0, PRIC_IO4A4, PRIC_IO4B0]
0x494 PRIC_IO494 — Memory Region Proection for AHB Masters Register \#37
  [31:8] RegionNEndAddr35129 — Region #N End Address[35:12]
  [7:2] RegionNReadGroup9 — Region #N Read Group
  [1] EnblRstTolerance9 — Enable Reset Tolerance
    0=Reset_By_SRST; 1=Reset_By_SRST_And_PSP_Reset
  [0] RegionNWrProt9 — Region #N Write Protection
0x498 PRIC_IO498 — Memory Region Proection for AHB Masters Register \#38
  [31:0] RegionNWrMasters9 — Region #N Write Masters
0x49C PRIC_IO49C — Memory Region Proection for AHB Masters Register \#39
  [31:0] RegionNReadMasters9 — Region #N Read Masters
0x4A0 PRIC_IO4A0 — Memory Region Proection for AHB Masters Register \#40
  [31:8] RegionNStartAddr351210 — Region #N Start Address[35:12]
  [7:2] RegionNWrGroup10 — Region #N Write Group
  [0] RegionNEnbl10 — Region #N Enable
0x4A4 PRIC_IO4A4 — Memory Region Proection for AHB Masters Register \#41
  [31:8] RegionNEndAddr351210 — Region #N End Address[35:12]
  [7:2] RegionNReadGroup10 — Region #N Read Group
  [1] EnblRstTolerance10 — Enable Reset Tolerance
    0=Reset_By_SRST; 1=Reset_By_SRST_And_PSP_Reset
  [0] RegionNWrProt10 — Region #N Write Protection
0x4A8 PRIC_IO4A8 — Memory Region Proection for AHB Masters Register \#42
  [31:0] RegionNWrMasters10 — Region #N Write Masters
0x4AC PRIC_IO4AC — Memory Region Proection for AHB Masters Register \#43
  [31:0] RegionNReadMasters10 — Region #N Read Masters
0x4B0 PRIC_IO4B0 — Memory Region Proection for AHB Masters Register \#44
  [31:8] RegionNStartAddr351211 — Region #N Start Address[35:12]
  [7:2] RegionNWrGroup11 — Region #N Write Group
  [0] RegionNEnbl11 — Region #N Enable
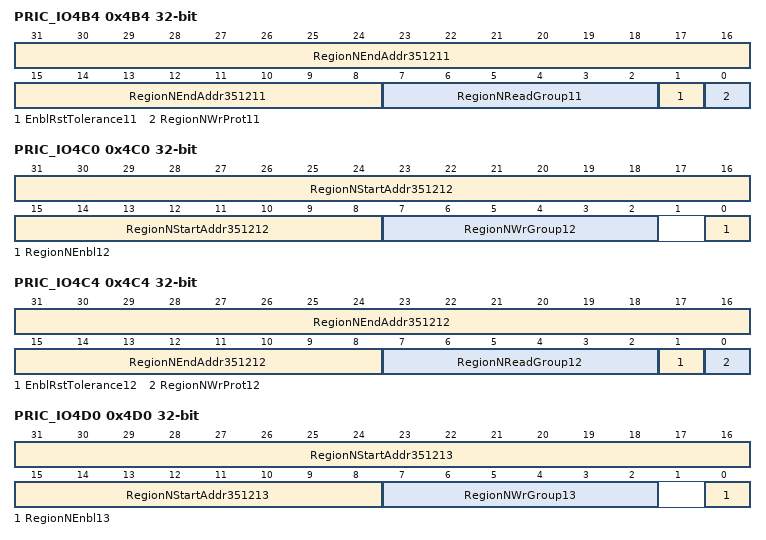
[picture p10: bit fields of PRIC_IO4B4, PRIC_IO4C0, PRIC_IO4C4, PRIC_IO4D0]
0x4B4 PRIC_IO4B4 — Memory Region Proection for AHB Masters Register \#45
  [31:8] RegionNEndAddr351211 — Region #N End Address[35:12]
  [7:2] RegionNReadGroup11 — Region #N Read Group
  [1] EnblRstTolerance11 — Enable Reset Tolerance
    0=Reset_By_SRST; 1=Reset_By_SRST_And_PSP_Reset
  [0] RegionNWrProt11 — Region #N Write Protection
0x4B8 PRIC_IO4B8 — Memory Region Proection for AHB Masters Register \#46
  [31:0] RegionNWrMasters11 — Region #N Write Masters
0x4BC PRIC_IO4BC — Memory Region Proection for AHB Masters Register \#47
  [31:0] RegionNReadMasters11 — Region #N Read Masters
0x4C0 PRIC_IO4C0 — Memory Region Proection for AHB Masters Register \#48
  [31:8] RegionNStartAddr351212 — Region #N Start Address[35:12]
  [7:2] RegionNWrGroup12 — Region #N Write Group
  [0] RegionNEnbl12 — Region #N Enable
0x4C4 PRIC_IO4C4 — Memory Region Proection for AHB Masters Register \#49
  [31:8] RegionNEndAddr351212 — Region #N End Address[35:12]
  [7:2] RegionNReadGroup12 — Region #N Read Group
  [1] EnblRstTolerance12 — Enable Reset Tolerance
    0=Reset_By_SRST; 1=Reset_By_SRST_And_PSP_Reset
  [0] RegionNWrProt12 — Region #N Write Protection
0x4C8 PRIC_IO4C8 — Memory Region Proection for AHB Masters Register \#40
  [31:0] RegionNWrMasters12 — Region #N Write Masters
0x4CC PRIC_IO4CC — Memory Region Proection for AHB Masters Register \#41
  [31:0] RegionNReadMasters12 — Region #N Read Masters
0x4D0 PRIC_IO4D0 — Memory Region Proection for AHB Masters Register \#52
  [31:8] RegionNStartAddr351213 — Region #N Start Address[35:12]
  [7:2] RegionNWrGroup13 — Region #N Write Group
  [0] RegionNEnbl13 — Region #N Enable
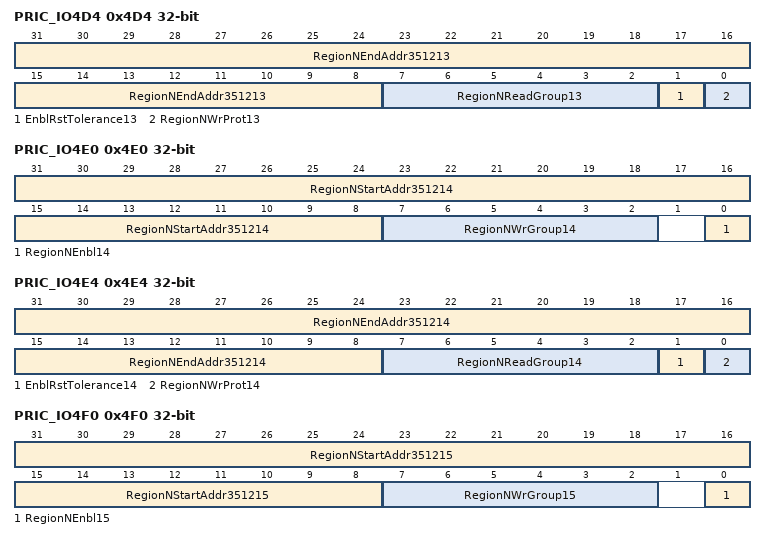
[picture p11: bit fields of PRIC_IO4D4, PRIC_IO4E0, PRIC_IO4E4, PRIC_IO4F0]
0x4D4 PRIC_IO4D4 — Memory Region Proection for AHB Masters Register \#53
  [31:8] RegionNEndAddr351213 — Region #N End Address[35:12]
  [7:2] RegionNReadGroup13 — Region #N Read Group
  [1] EnblRstTolerance13 — Enable Reset Tolerance
    0=Reset_By_SRST; 1=Reset_By_SRST_And_PSP_Reset
  [0] RegionNWrProt13 — Region #N Write Protection
0x4D8 PRIC_IO4D8 — Memory Region Proection for AHB Masters Register \#54
  [31:0] RegionNWrMasters13 — Region #N Write Masters
0x4DC PRIC_IO4DC — Memory Region Proection for AHB Masters Register \#55
  [31:0] RegionNReadMasters13 — Region #N Read Masters
0x4E0 PRIC_IO4E0 — Memory Region Proection for AHB Masters Register \#56
  [31:8] RegionNStartAddr351214 — Region #N Start Address[35:12]
  [7:2] RegionNWrGroup14 — Region #N Write Group
  [0] RegionNEnbl14 — Region #N Enable
0x4E4 PRIC_IO4E4 — Memory Region Proection for AHB Masters Register \#57
  [31:8] RegionNEndAddr351214 — Region #N End Address[35:12]
  [7:2] RegionNReadGroup14 — Region #N Read Group
  [1] EnblRstTolerance14 — Enable Reset Tolerance
    0=Reset_By_SRST; 1=Reset_By_SRST_And_PSP_Reset
  [0] RegionNWrProt14 — Region #N Write Protection
0x4E8 PRIC_IO4E8 — Memory Region Proection for AHB Masters Register \#58
  [31:0] RegionNWrMasters14 — Region #N Write Masters
0x4EC PRIC_IO4EC — Memory Region Proection for AHB Masters Register \#59
  [31:0] RegionNReadMasters14 — Region #N Read Masters
0x4F0 PRIC_IO4F0 — Memory Region Proection for AHB Masters Register \#60
  [31:8] RegionNStartAddr351215 — Region #N Start Address[35:12]
  [7:2] RegionNWrGroup15 — Region #N Write Group
  [0] RegionNEnbl15 — Region #N Enable
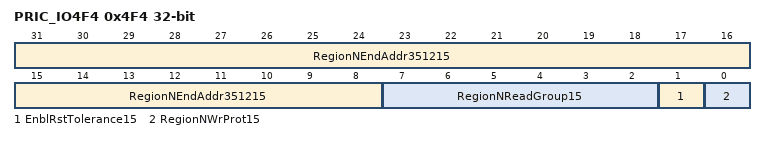
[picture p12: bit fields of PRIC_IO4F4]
0x4F4 PRIC_IO4F4 — Memory Region Proection for AHB Masters Register \#61
  [31:8] RegionNEndAddr351215 — Region #N End Address[35:12]
  [7:2] RegionNReadGroup15 — Region #N Read Group
  [1] EnblRstTolerance15 — Enable Reset Tolerance
    0=Reset_By_SRST; 1=Reset_By_SRST_And_PSP_Reset
  [0] RegionNWrProt15 — Region #N Write Protection
0x4F8 PRIC_IO4F8 — Memory Region Proection for AHB Masters Register \#62
  [31:0] RegionNWrMasters15 — Region #N Write Masters
0x4FC PRIC_IO4FC — Memory Region Proection for AHB Masters Register \#63
  [31:0] RegionNReadMasters15 — Region #N Read Masters
